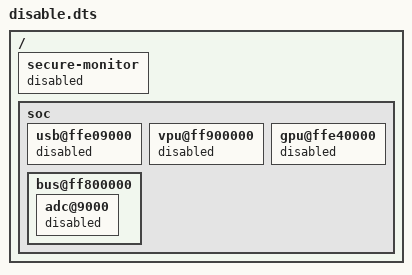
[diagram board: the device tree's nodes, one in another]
/ {
    secure-monitor {
		status = "disabled";
	};

    soc {
        /delete-node/ usb@ffe09000;

        usb@ffe09000 {
            status = "disabled";
        };
        
        vpu@ff900000 {
            status = "disabled";
        };

        gpu@ffe40000 {
            status = "disabled";
        };

        bus@ff800000 {
            adc@9000 {
                status = "disabled";
            };
        };
    };
};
